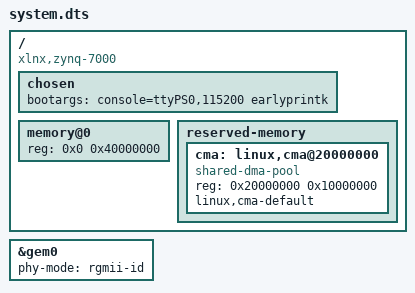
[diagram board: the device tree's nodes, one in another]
/dts-v1/;

#include "zynq-7000.dtsi"

/ {
    compatible = "xlnx,zynq-7000";

    chosen {
        bootargs = "console=ttyPS0,115200 earlyprintk";
    };

    memory@0 {
        device_type = "memory";
        reg = <0x0 0x40000000>;  // 1GB RAM for Z7020
    };

    reserved-memory {
        #address-cells = <1>;
        #size-cells = <1>;
        ranges;

        cma: linux,cma@20000000 {
            compatible = "shared-dma-pool";
            reg = <0x20000000 0x10000000>;  // 256MB CMA
            linux,cma-default;
        };
    };
};

&gem0 {
    status = "okay";
    phy-mode = "rgmii-id";
};

// Add other peripherals as needed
